AUTOSAR XML (schema 4-0-3)
package /ComponentTypes
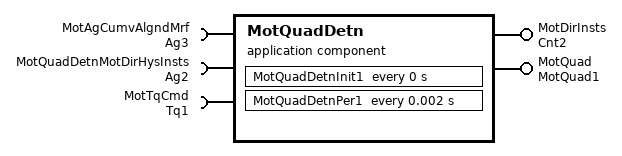
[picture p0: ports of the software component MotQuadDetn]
  application sw component type MotQuadDetn
    provide port MotDirInsts: nonqueued-sender-com-spec{data-element=Val, init-value=1}, provided-interface=Cnt2
    provide port MotQuad: nonqueued-sender-com-spec{data-element=Val, init-value=1}, provided-interface=MotQuad1
    require port MotAgCumvAlgndMrf: nonqueued-receiver-com-spec{data-element=Val, filter=data-filter-type=ALWAYS, init-value=0}, required-interface=Ag3
    require port MotQuadDetnMotDirHysInsts: parameter-require-com-spec{init-value=2.5, parameter=Val}, required-interface=Ag2
    require port MotTqCmd: nonqueued-receiver-com-spec{data-element=Val, filter=data-filter-type=ALWAYS, init-value=0}, required-interface=Tq1
    behavior MotQuadDetn_InternalBehavior: data-type-mapping=Nexteer
      ar-typed-per-instance-memorys:
        5 x data, all with sw-calibration-access=READ-ONLY:
          dMotQuadDetnMotAgCumDelta: type=Ag7
          dMotQuadDetnTqCmdSign: type=Cnt2
          MotAgCumPrev: type=Ag7
          MotDirInstsPrev: type=Cnt2
          MotTqCmdSignPrev: type=Cnt2
      timing event MotQuadDetn_InitEvent: start-on-event=MotQuadDetnInit1, period=0
      timing event TMT_MotQuadDetnPer1: start-on-event=MotQuadDetnPer1, period=0.002
      runnable MotQuadDetnInit1
      runnable MotQuadDetnPer1
        data-receive-point-by-arguments:
          access REC_MotAgCumvAlgndMrf_Val: accessed-variable=MotAgCumvAlgndMrf.Val
          access REC_TqCmd_Val: accessed-variable=MotTqCmd.Val
        data-send-points:
          access SEND_MotDirInsts_Val: accessed-variable=MotDirInsts.Val
          access SEND_MotQuad_Val: accessed-variable=MotQuad.Val
  swc implementation MotQuadDetn_Implementation: behavior=MotQuadDetn_InternalBehavior
    code-descriptors:
      code Default: artifact-descriptors=autosar-engineering-object={short-label=Default, category=SWSRC}
